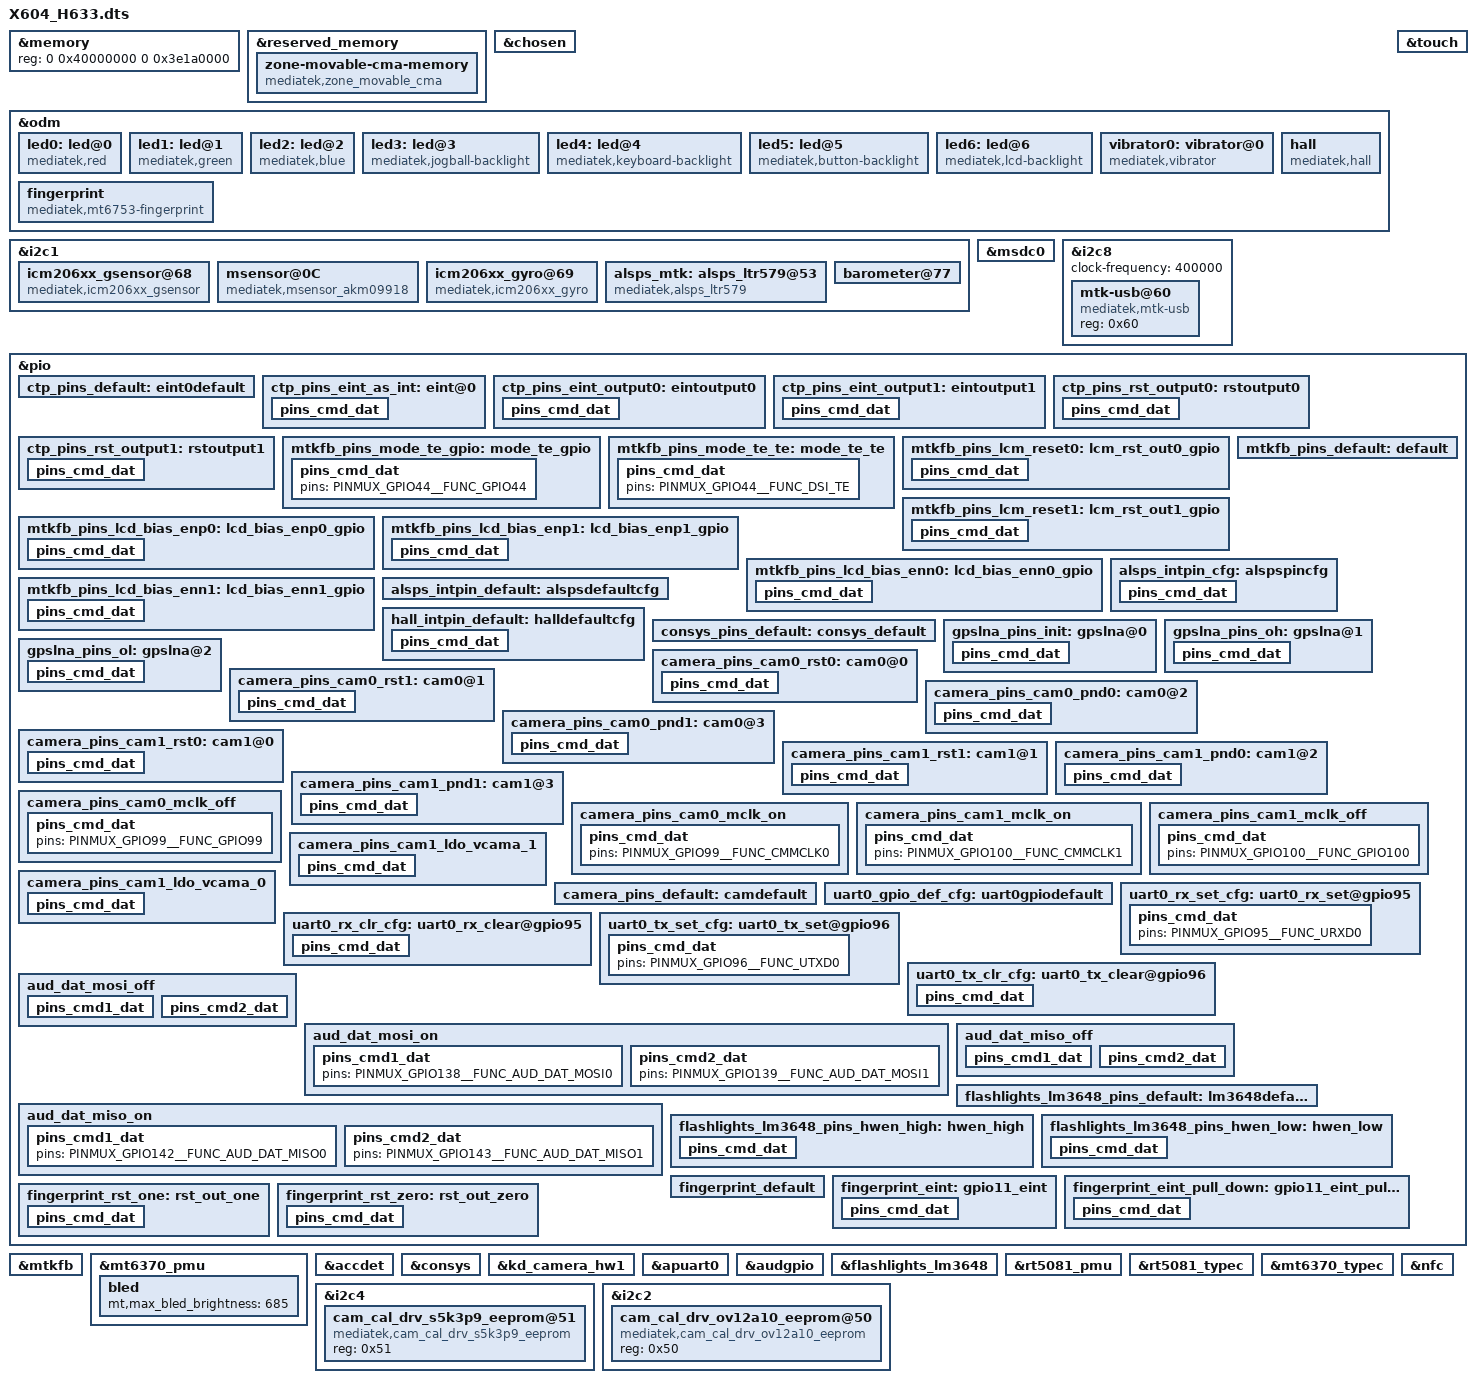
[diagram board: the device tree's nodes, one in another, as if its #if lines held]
#include <generated/autoconf.h>
/dts-v1/;

#ifdef CONFIG_MTK_DTBO_FEATURE
/plugin/;
#include <dt-bindings/interrupt-controller/irq.h>
#include <dt-bindings/interrupt-controller/arm-gic.h>
#include <dt-bindings/mmc/mt6763-msdc.h>
#include <dt-bindings/pinctrl/mt6763-pinfunc.h>
#else
#include "mt6763.dts"
#endif


&memory {
		device_type = "memory";
		reg = <0 0x40000000 0 0x3e1a0000>;
};

&reserved_memory {
		#address-cells = <2>;
		#size-cells = <2>;
		ranges;

		zone-movable-cma-memory {
			compatible = "mediatek,zone_movable_cma";
			size = <0 0xffc00000>;
			alignment = <0 0x10000000>;
			alloc-ranges = <0 0xc0000000 1 0x00000000>;
	};
};


/* chosen */
&chosen {
		bootargs = "console=tty0 console=ttyMT0,921600n1 root=/dev/ram initrd=0x45000000,\
0x1000000 loglevel=8 androidboot.selinux=permissive androidboot.hardware=mt6763 initcall_debug=1 maxcpus=1";
		/* fpga may has no lk, we need to specify display info here */
		/* fb buffer is reserved using this dts by memory node above */
		atag,videolfb-fb_base_h = <0x0>;
		atag,videolfb-fb_base_l = <0x5e605000>;
		atag,videolfb-islcmfound = <1>;
		/* because no lk, so lcm is not inited */
		atag,videolfb-islcm_inited = <0>;
		atag,videolfb-fps= <6000>;
		atag,videolfb-vramSize= <0x017bb000>;
		atag,videolfb-lcmname= "nt35695B_fhd_dsi_cmd_auo_rt5081_drv";
};

&odm {
	led0:led@0 {
		compatible = "mediatek,red";
		led_mode = <0>;
		data = <1>;
		pwm_config = <0 0 0 0 0>;
	};
	led1:led@1 {
		compatible = "mediatek,green";
		led_mode = <0>;
		data = <1>;
		pwm_config = <0 0 0 0 0>;
	};
	led2:led@2 {
		compatible = "mediatek,blue";
		led_mode = <0>;
		data = <1>;
		pwm_config = <0 0 0 0 0>;
	};
	led3:led@3 {
		compatible = "mediatek,jogball-backlight";
		led_mode = <0>;
		data = <1>;
		pwm_config = <0 0 0 0 0>;
	};
	led4:led@4 {
		compatible = "mediatek,keyboard-backlight";
		led_mode = <0>;
		data = <1>;
		pwm_config = <0 0 0 0 0>;
	};
	led5:led@5 {
		compatible = "mediatek,button-backlight";
		led_mode = <0>;
		data = <1>;
		pwm_config = <0 0 0 0 0>;
	};
	led6:led@6 {
		compatible = "mediatek,lcd-backlight";
		led_mode = <5>;
		data = <1>;
		pwm_config = <0 3 0 0 0>;
	};
	vibrator0:vibrator@0 {
		compatible = "mediatek,vibrator";
		vib_timer = <25>;
		vib_limit = <9>;
		vib_vol= <11>;
	};
        hall: hall {
                compatible = "mediatek,hall";
                interrupt-parent = <&eintc>;
                interrupts = <7 IRQ_TYPE_LEVEL_LOW>;
                debounce = <7 0>;
                pinctrl-names = "default";
                pinctrl-0 = <&hall_intpin_default>;
                status = "okay";
        };
	/*add fingerprint by sunware*/
	fingerprint:fingerprint {
		compatible = "mediatek,mt6753-fingerprint";
		interrupt-parent = <&eintc>;
		interrupts = <8 1>;
		debounce = <8 0>;

		pinctrl-names ="fingerprint_default",
			"fingerprint_pin_irq",
			"fingerprint_eint_pull_down",
			"fingerprint_reset_high",
			"fingerprint_reset_low",
			"fingerprint_power_high",
			"fingerprint_power_low";

		pinctrl-0 = <&fingerprint_default>;
		pinctrl-1 = <&fingerprint_eint>;
		pinctrl-2 = <&fingerprint_eint_pull_down>;
		pinctrl-3 = <&fingerprint_rst_one>;
		pinctrl-4 = <&fingerprint_rst_zero>;
		status = "okay";
	};
        /*add OSODEV-1176 by chengwenwu 20171123 end*/
};

&i2c1 {
/*  start sensor */
	icm206xx_gsensor@68 {
                compatible = "mediatek,icm206xx_gsensor";
		i2c_num	= <1>;
                reg = <0x68>;
                i2c_addr = <0x68 0 0 0>;
                direction = <4>;
		power_id = <0xffff>;
		power_vol = <0>;
		firlen = <0>;
		is_batch_supported = <0>;
                status = "okay";
	};

	msensor@0C {
		compatible = "mediatek,msensor_akm09918";
		i2c_num = <1>;
		reg = <0x0C>;
		i2c_addr = <0x0C 0 0 0>;
		direction = <5>;
		power_id = <0xffff>;
		power_vol = <0>;
		is_batch_supported = <0>;
		status = "okay";
	};

	icm206xx_gyro@69 {
                compatible = "mediatek,icm206xx_gyro";
                i2c_num = <1>;
                reg = <0x69>;
		i2c_addr = <0x68 0 0 0>;
		direction = <4>;
		power_id = <0xffff>;
		power_vol = <0>;
		firlen = <0>;
		is_batch_supported = <0>;
                status = "okay";
	};

        alsps_mtk:alsps_ltr579@53 {
                compatible = "mediatek,alsps_ltr579";
                pinctrl-names = "pin_default", "pin_cfg";
                pinctrl-0 = <&alsps_intpin_default>;
                pinctrl-1 = <&alsps_intpin_cfg>;
                interrupt-parent = <&eintc>;
                interrupts = <5 IRQ_TYPE_LEVEL_LOW>;
                debounce = <5 0>;
                status = "okay";
                /* customization */
                i2c_num = <1>;
                reg = <0x53>;
                i2c_addr = <0x53 0 0 0>;
                polling_mode_ps = <0>;
                polling_mode_als = <1>;
                power_id = <0xffff>;
                power_vol = <0>;
                als_level = <0 110 220 340 570 900 1130 1600 2000 4000 12000 25000 30000 40000 60000>;
                als_value = <0 100 200 300 500 800 1000 1200 1500 3000 8000 15000 20000 20000 20000 20000>;
                ps_dynamic_cali = <55 105 115 125 135 145 155 1600 20 40 50 60 70 80 90 1550>;
                ps_setting = <0x36 0x10 0x5c 100 0x01>;
                als_setting = <0x22 0x04 100 48 10 4368 4927 3790 4776>;
                ps_threshold_high =  <500>;
                ps_threshold_low =  <400>;
                is_batch_supported_ps = <0>;
                is_batch_supported_als = <0>;
        };

	barometer@77 {
		i2c_num = <1>;
		i2c_addr = <0x77 0 0 0>;
		direction = <0>;
		power_id = <0xffff>;
		power_vol = <0>;
		firlen = <32>;
		is_batch_supported = <0>;
	};
/* end sensor */
};

&msdc0 {
	status = "okay";
};

&i2c8 {
	#address-cells = <1>;
	#size-cells = <0>;
	clock-frequency = <400000>;

	mtk-usb@60 {
		compatible = "mediatek,mtk-usb";
		reg = <0x60>;
		status = "okay";
	};
};

/* TOUCH start */
&touch {
	tpd-resolution = <1080 1920>;
	use-tpd-button = <1>;
	tpd-key-num = <3>;
	tpd-key-local= <139 172 158 0>;
	tpd-key-dim-local = <90 883 100 40 230 883 100 40 370 883 100 40 0 0 0 0>;
	tpd-max-touch-num = <5>;
	tpd-filter-enable = <1>;
	tpd-filter-pixel-density = <146>;
	tpd-filter-custom-prameters = <0 0 0 0 0 0 0 0 0 0 0 0>;
	tpd-filter-custom-speed = <0 0 0>;
	pinctrl-names = "default", "state_eint_as_int", "state_eint_output0", "state_eint_output1",
		"state_rst_output0", "state_rst_output1";
	pinctrl-0 = <&ctp_pins_default>;
	pinctrl-1 = <&ctp_pins_eint_as_int>;
	pinctrl-2 = <&ctp_pins_eint_output0>;
	pinctrl-3 = <&ctp_pins_eint_output1>;
	pinctrl-4 = <&ctp_pins_rst_output0>;
	pinctrl-5 = <&ctp_pins_rst_output1>;
	status = "okay";
};
&pio {
	ctp_pins_default: eint0default {
	};
	ctp_pins_eint_as_int: eint@0 {
		pins_cmd_dat {
			pins = <PINMUX_GPIO1__FUNC_GPIO1>;
			slew-rate = <0>;
			bias-disable;
		};
	};
	ctp_pins_eint_output0: eintoutput0 {
		pins_cmd_dat {
			pins = <PINMUX_GPIO1__FUNC_GPIO1>;
			slew-rate = <1>;
			output-low;
		};
	};
	ctp_pins_eint_output1: eintoutput1 {
		pins_cmd_dat {
			pins = <PINMUX_GPIO1__FUNC_GPIO1>;
			slew-rate = <1>;
			output-high;
		};
	};
	ctp_pins_rst_output0: rstoutput0 {
		pins_cmd_dat {
			pins = <PINMUX_GPIO2__FUNC_GPIO2>;
			slew-rate = <1>;
			output-low;
		};
	};
	ctp_pins_rst_output1: rstoutput1 {
		pins_cmd_dat {
			pins = <PINMUX_GPIO2__FUNC_GPIO2>;
			slew-rate = <1>;
			output-high;
		};
	};
};
/* TOUCH end */

&pio {

	mtkfb_pins_mode_te_gpio: mode_te_gpio {
		pins_cmd_dat {
			pins = <PINMUX_GPIO44__FUNC_GPIO44>;
		};
	};

	mtkfb_pins_mode_te_te: mode_te_te {
		pins_cmd_dat {
			pins = <PINMUX_GPIO44__FUNC_DSI_TE>;
		};
	};

	mtkfb_pins_lcm_reset0: lcm_rst_out0_gpio {
		pins_cmd_dat {
			pins = <PINMUX_GPIO45__FUNC_GPIO45>;
			slew-rate = <1>;
			output-low;
		};
	};

	mtkfb_pins_lcm_reset1: lcm_rst_out1_gpio {
		pins_cmd_dat {
			pins = <PINMUX_GPIO45__FUNC_GPIO45>;
			slew-rate = <1>;
			output-high;
		};
	};

	mtkfb_pins_lcd_bias_enp0: lcd_bias_enp0_gpio {
		pins_cmd_dat {
			pins = <PINMUX_GPIO13__FUNC_GPIO13>;
			slew-rate = <1>;
			output-low;
		};
	};

	mtkfb_pins_lcd_bias_enp1: lcd_bias_enp1_gpio {
		pins_cmd_dat {
			pins = <PINMUX_GPIO13__FUNC_GPIO13>;
			slew-rate = <1>;
			output-high;
		};
	};

	mtkfb_pins_lcd_bias_enn0: lcd_bias_enn0_gpio {
		pins_cmd_dat {
			pins = <PINMUX_GPIO14__FUNC_GPIO14>;
			slew-rate = <1>;
			output-low;
		};
	};

	mtkfb_pins_lcd_bias_enn1: lcd_bias_enn1_gpio {
		pins_cmd_dat {
			pins = <PINMUX_GPIO14__FUNC_GPIO14>;
			slew-rate = <1>;
			output-high;
		};
	};
	mtkfb_pins_default: default {
	};

};

&mtkfb {
	pinctrl-names = "default", "mode_te_gpio", "mode_te_te", "lcm_rst_out0_gpio",
	"lcm_rst_out1_gpio", "lcd_bias_enp0_gpio", "lcd_bias_enp1_gpio";
	pinctrl-0 = <&mtkfb_pins_default>;
	pinctrl-1 = <&mtkfb_pins_mode_te_gpio>;
	pinctrl-2 = <&mtkfb_pins_mode_te_te>;
	pinctrl-3 = <&mtkfb_pins_lcm_reset0>;
	pinctrl-4 = <&mtkfb_pins_lcm_reset1>;
	pinctrl-5 = <&mtkfb_pins_lcd_bias_enp0>;
	pinctrl-6 = <&mtkfb_pins_lcd_bias_enp1>;
	pinctrl-7 = <&mtkfb_pins_lcd_bias_enn0>;
	pinctrl-8 = <&mtkfb_pins_lcd_bias_enn1>;
	status = "okay";
};

&mt6370_pmu {
	bled {
		mt,max_bled_brightness = <685>; /* we have 11 bit resolution, quantize in driver */
						/* maximum 2047 */
	};
};

/* sensor gpio standization */
&pio {
	alsps_intpin_cfg: alspspincfg {

		pins_cmd_dat {
			pins = <PINMUX_GPIO5__FUNC_GPIO5>;
			slew-rate = <0>;
			bias-pull-up = <00>;
		};
	};

	alsps_intpin_default: alspsdefaultcfg {

	};
        hall_intpin_default: halldefaultcfg {
                pins_cmd_dat {
                        pins = <PINMUX_GPIO7__FUNC_GPIO7>;
                        slew-rate = <0>;
                        bias-pull-up = <00>;
                        status = "okay";
                };
        };
};
/* sensor end */

/* accdet start */
&accdet {
	/* accdet micbias voltage: 0x07,2.7v;0x05,2.5v;0x02,1.9v */
	accdet-mic-vol = <6>;
	headset-mode-setting = <0x500 0x500 1 0x1f0 0x800 0x800 0x20 0x44>;
	accdet-plugout-debounce = <1>;
	/*1:ACC mode, 2:low cost without in bias, 6:low cost with in bias*/
	accdet-mic-mode = <2>;
	/* eint_level_trigger: 8,LEVEL_LOW(default);4,LEVEL_HIGH;others,LEVEL_LOW */
	headset-eint-level-pol = <8>;
	/*0--MD_MAX--UP_MAX--DW_MAX*/
	headset-three-key-threshold = <0 80 220 400>;
	headset-three-key-threshold-CDD = <0 121 192 600>;
	/*0--MD_MAX--VOICE_MAX--UP_MAX--DW_MAX*/
	headset-four-key-threshold = <0 58 121 192 400>;
	status = "okay";
};
/* accdet end */

/* CONSYS GPIO standardization */
&pio {
	consys_pins_default: consys_default {
	};
	gpslna_pins_init: gpslna@0 {
		pins_cmd_dat {
			pins = <PINMUX_GPIO107__FUNC_GPIO107>;
			slew-rate = <0>;
			bias-disable;
			output-low;
		};
	};
	gpslna_pins_oh: gpslna@1 {
		pins_cmd_dat {
			pins = <PINMUX_GPIO107__FUNC_GPIO107>;
			slew-rate = <1>;
			output-high;
		};
	};
	gpslna_pins_ol: gpslna@2 {
		pins_cmd_dat {
			pins = <PINMUX_GPIO107__FUNC_GPIO107>;
			slew-rate = <1>;
			output-low;
		};
	};
};
&consys {
	pinctrl-names = "default", "gps_lna_state_init", "gps_lna_state_oh", "gps_lna_state_ol";
	pinctrl-0 = <&consys_pins_default>;
	pinctrl-1 = <&gpslna_pins_init>;
	pinctrl-2 = <&gpslna_pins_oh>;
	pinctrl-3 = <&gpslna_pins_ol>;
	status = "okay";
};
/* CONSYS end */

 /* CAMERA GPIO standardization */
&pio {
	camera_pins_cam0_rst0: cam0@0 {
		pins_cmd_dat {
			pins = <PINMUX_GPIO101__FUNC_GPIO101>;
			slew-rate = <1>; /*direction 0:in, 1:out*/
			output-low;/*direction out used only. output_low or high*/
		};
	};
	camera_pins_cam0_rst1: cam0@1 {
		pins_cmd_dat {
			pins = <PINMUX_GPIO101__FUNC_GPIO101>;
			slew-rate = <1>;
			output-high;
		};
	};
	camera_pins_cam0_pnd0: cam0@2 {
		pins_cmd_dat {
			pins = <PINMUX_GPIO97__FUNC_GPIO97>;
			slew-rate = <1>;
			output-low;
		};
	};
	camera_pins_cam0_pnd1: cam0@3 {
		pins_cmd_dat {
			pins = <PINMUX_GPIO97__FUNC_GPIO97>;
			slew-rate = <1>;
			output-high;
		};
	};
	camera_pins_cam1_rst0: cam1@0 {
		pins_cmd_dat {
			pins = <PINMUX_GPIO102__FUNC_GPIO102>;
			slew-rate = <1>; /*direction 0:in, 1:out*/
			output-low;/*direction out used only. output_low or high*/
		};
	};
	camera_pins_cam1_rst1: cam1@1 {
		pins_cmd_dat {
			pins = <PINMUX_GPIO102__FUNC_GPIO102>;
			slew-rate = <1>;
			output-high;
		};
	};
	camera_pins_cam1_pnd0: cam1@2 {
		pins_cmd_dat {
			pins = <PINMUX_GPIO98__FUNC_GPIO98>;
			slew-rate = <1>;
			output-low;
		};
	};
	camera_pins_cam1_pnd1: cam1@3 {
		pins_cmd_dat {
			pins = <PINMUX_GPIO98__FUNC_GPIO98>;
			slew-rate = <1>;
			output-high;
		};
	};
	camera_pins_cam0_mclk_on: camera_pins_cam0_mclk_on {
		pins_cmd_dat {
			pins = <PINMUX_GPIO99__FUNC_CMMCLK0>;
		};
	};
	camera_pins_cam0_mclk_off: camera_pins_cam0_mclk_off {
		pins_cmd_dat {
			pins = <PINMUX_GPIO99__FUNC_GPIO99>;
		};
	};
	camera_pins_cam1_mclk_on: camera_pins_cam1_mclk_on {
		pins_cmd_dat {
			pins = <PINMUX_GPIO100__FUNC_CMMCLK1>;
		};
	};
	camera_pins_cam1_mclk_off: camera_pins_cam1_mclk_off {
		pins_cmd_dat {
			pins = <PINMUX_GPIO100__FUNC_GPIO100>;
		};
	};
	camera_pins_cam1_ldo_vcama_1: camera_pins_cam1_ldo_vcama_1 {
		pins_cmd_dat {
			pins = <PINMUX_GPIO20__FUNC_GPIO20>;
			slew-rate = <1>;
			output-high;
			//pins = <PINMUX_GPIO52__FUNC_BPI_ANT2>;
		};
	};
	camera_pins_cam1_ldo_vcama_0: camera_pins_cam1_ldo_vcama_0 {
		pins_cmd_dat {
			pins = <PINMUX_GPIO20__FUNC_GPIO20>;
			slew-rate = <1>;
			output-low;
			//pins = <PINMUX_GPIO52__FUNC_GPIO52>;
		};
	};
	camera_pins_default: camdefault {
	};

};

&kd_camera_hw1 {
	pinctrl-names = "default",
			"cam0_rst0", "cam0_rst1", "cam0_pnd0", "cam0_pnd1",
			"cam1_rst0", "cam1_rst1", "cam1_pnd0", "cam1_pnd1",
			"cam0_mclk_on", "cam0_mclk_off",
			"cam1_mclk_on", "cam1_mclk_off",
			"cam1_ldo_vcama_1","cam1_ldo_vcama_0";

	pinctrl-0 = <&camera_pins_default>;
	pinctrl-1 = <&camera_pins_cam0_rst0>;
	pinctrl-2 = <&camera_pins_cam0_rst1>;
	pinctrl-3 = <&camera_pins_cam0_pnd0>;
	pinctrl-4 = <&camera_pins_cam0_pnd1>;
	pinctrl-5 = <&camera_pins_cam1_rst0>;
	pinctrl-6 = <&camera_pins_cam1_rst1>;
	pinctrl-7 = <&camera_pins_cam1_pnd0>;
	pinctrl-8 = <&camera_pins_cam1_pnd1>;
	pinctrl-9 = <&camera_pins_cam0_mclk_on>;
	pinctrl-10 = <&camera_pins_cam0_mclk_off>;
	pinctrl-11 = <&camera_pins_cam1_mclk_on>;
	pinctrl-12 = <&camera_pins_cam1_mclk_off>;
	pinctrl-13 = <&camera_pins_cam1_ldo_vcama_1>;
	pinctrl-14 = <&camera_pins_cam1_ldo_vcama_0>;
	status = "okay";

};
/* CAMERA GPIO end */

/* UART GPIO */
&apuart0 {
	pinctrl-names = "uart0_gpio_default",
			"uart0_rx_set",
			"uart0_rx_clear",
			"uart0_tx_set",
			"uart0_tx_clear";
	pinctrl-0 = <&uart0_gpio_def_cfg>;
	pinctrl-1 = <&uart0_rx_set_cfg>;
	pinctrl-2 = <&uart0_rx_clr_cfg>;
	pinctrl-3 = <&uart0_tx_set_cfg>;
	pinctrl-4 = <&uart0_tx_clr_cfg>;
	status = "okay";
};

&pio {
	/* UART GPIO Settings - Start */
	/* UART0: rx set, rx clear, tx clear, tx clear*/
	uart0_gpio_def_cfg:uart0gpiodefault {

	};
	uart0_rx_set_cfg:uart0_rx_set@gpio95 {
		pins_cmd_dat {
			pins = <PINMUX_GPIO95__FUNC_URXD0>;
		};
	};
	uart0_rx_clr_cfg:uart0_rx_clear@gpio95 {
		pins_cmd_dat {
			pins = <PINMUX_GPIO95__FUNC_GPIO95>;
			slew-rate = <1>;
			output-high;
		};
	};
	uart0_tx_set_cfg:uart0_tx_set@gpio96 {
		pins_cmd_dat {
			pins = <PINMUX_GPIO96__FUNC_UTXD0>;
		};
	};
	uart0_tx_clr_cfg:uart0_tx_clear@gpio96 {
		pins_cmd_dat {
			pins = <PINMUX_GPIO96__FUNC_GPIO96>;
			slew-rate = <1>;
			output-high;
		};
	};
};/* UART GPIO end */

/* IRTX GPIO end */
/*
&irtx_pwm {
	pinctrl-names = "irtx_gpio_led_default", "irtx_gpio_led_set";
	pinctrl-0 = <&irtx_gpio_led_default>;
	pinctrl-1 = <&irtx_gpio_led_set>;
	status = "disabled";
};
&pio {
	// * IRTX GPIO Settings -Start * /
	// * default: GPIO0, output, high * /
	irtx_gpio_led_default:irtx_gpio_led_def@gpio58 {
		pins_cmd_dat {
			pins = <PINMUX_GPIO58__FUNC_GPIO58>;
			slew-rate = <1>;
			bias-disable;
			output-low;
			input-schmitt-enable = <0>;
		};
	};

	irtx_gpio_led_set:irtx_gpio_led_set@gpio58 {
		pins_cmd_dat {
			pins = <PINMUX_GPIO58__FUNC_PWM_B>;
			slew-rate = <1>;
			output-high;
		};
	};
}; */ /* IRTX GPIO Settings -End */

/* AUDIO GPIO standardization */
&audgpio {
        extamp_gpio = <&pio 92 0>;
        extamp_mode = <3>;
        extamp_speech_mode = <3>;
	pinctrl-names = "aud_dat_mosi_off",
			"aud_dat_mosi_on",
			"aud_dat_miso_off",
			"aud_dat_miso_on";
	pinctrl-0 = <&aud_dat_mosi_off>;
	pinctrl-1 = <&aud_dat_mosi_on>;
	pinctrl-2 = <&aud_dat_miso_off>;
	pinctrl-3 = <&aud_dat_miso_on>;
	status = "okay";
};

&pio {
	aud_dat_mosi_off: aud_dat_mosi_off {
		pins_cmd1_dat {
			pins = <PINMUX_GPIO138__FUNC_GPIO138>;
			input-enable;
			slew-rate = <0>;
			bias-disable;
		};
		pins_cmd2_dat {
			pins = <PINMUX_GPIO139__FUNC_GPIO139>;
			input-enable;
			slew-rate = <0>;
			bias-disable;
		};
	};

	aud_dat_mosi_on: aud_dat_mosi_on {
		pins_cmd1_dat {
			pins = <PINMUX_GPIO138__FUNC_AUD_DAT_MOSI0>;
		};
		pins_cmd2_dat {
			pins = <PINMUX_GPIO139__FUNC_AUD_DAT_MOSI1>;
		};
	};

	aud_dat_miso_off: aud_dat_miso_off {
		pins_cmd1_dat {
			pins = <PINMUX_GPIO142__FUNC_GPIO142>;
			input-enable;
			slew-rate = <0>;
			bias-disable;
		};
		pins_cmd2_dat {
			pins = <PINMUX_GPIO143__FUNC_GPIO143>;
			input-enable;
			slew-rate = <0>;
			bias-disable;
		};
	};

	aud_dat_miso_on: aud_dat_miso_on {
		pins_cmd1_dat {
			pins = <PINMUX_GPIO142__FUNC_AUD_DAT_MISO0>;
		};
		pins_cmd2_dat {
			pins = <PINMUX_GPIO143__FUNC_AUD_DAT_MISO1>;
		};
	};
};
/* AUDIO end */
&pio {
	flashlights_lm3648_pins_default: lm3648default {
	};

	flashlights_lm3648_pins_hwen_high: hwen_high {
		pins_cmd_dat {
			pins = <PINMUX_GPIO90__FUNC_GPIO90>;
			slew-rate = <1>;
			output-high;
		};
	};

	flashlights_lm3648_pins_hwen_low: hwen_low {
		pins_cmd_dat {
			pins = <PINMUX_GPIO90__FUNC_GPIO90>;
			slew-rate = <1>;
			output-low;
		};
	};
};

&flashlights_lm3648 {
	pinctrl-names = "default", "hwen_high", "hwen_low";
	pinctrl-0 = <&flashlights_lm3648_pins_default>;
	pinctrl-1 = <&flashlights_lm3648_pins_hwen_high>;
	pinctrl-2 = <&flashlights_lm3648_pins_hwen_low>;
	status = "okay";
};

#ifdef CONFIG_MFD_RT5081_PMU
&rt5081_pmu {
	rt,intr_gpio_num = <91>; /* direct defined GPIO num */
	rt,intr_gpio = <&pio 91 0x0>;
};
#endif
#ifdef CONFIG_TCPC_RT5081
&rt5081_typec {
	rt5081pd,intr_gpio_num = <41>; /* direct defined GPIO num */
	rt5081pd,intr_gpio = <&pio 41 0x0>;
};
#endif
#ifdef CONFIG_MFD_MT6370_PMU
&mt6370_pmu {
	mt6370,intr_gpio_num = <10>; /* direct defined GPIO num */
	mt6370,intr_gpio = <&pio 10 0x0>;
};
#endif
#ifdef CONFIG_TCPC_MT6370
&mt6370_typec {
	mt6370pd,intr_gpio_num = <11>; /* direct defined GPIO num */
	mt6370pd,intr_gpio = <&pio 11 0x0>;
};
#endif


&nfc {
	gpio-rst = <21>;
	gpio-rst-std = <&pio 21 0x0>;
	gpio-irq = <22>;
	gpio-irq-std = <&pio 22  0x0>;
};

&mtkfb {
	partial-update = <1>;
	status = "okay";
};
/*add fingerprint by sunware*/
&pio {
	fingerprint_default: fingerprint_default {
	};

	fingerprint_eint: gpio11_eint {
		pins_cmd_dat {
			pins = <PINMUX_GPIO8__FUNC_GPIO8>;
			slew-rate = <0>;
			bias-disable;
		};
	};

	fingerprint_eint_pull_down: gpio11_eint_pull_down {
		pins_cmd_dat {
			pins = <PINMUX_GPIO8__FUNC_GPIO8>;
			slew-rate = <0>;
			bias-pull-down = <00>;
			output-low;
		};
	};

	fingerprint_rst_one: rst_out_one {
		pins_cmd_dat {
			pins = <PINMUX_GPIO19__FUNC_GPIO19>;
			slew-rate = <1>;
			bias-disable;
			output-high;
		};
	};

	fingerprint_rst_zero: rst_out_zero {
		pins_cmd_dat {
			pins = <PINMUX_GPIO19__FUNC_GPIO19>;
			slew-rate = <1>;
			bias-disable;
			output-low;
		};
	};

};
/* end of fingerprint*/
&i2c4{
	cam_cal_drv_s5k3p9_eeprom@51 {
		compatible = "mediatek,cam_cal_drv_s5k3p9_eeprom";
		reg = <0x51>;
	};
};
&i2c2{
	cam_cal_drv_ov12a10_eeprom@50 {
		compatible = "mediatek,cam_cal_drv_ov12a10_eeprom";
		reg = <0x50>;
	};
};
#include <X604_H633/cust.dtsi>
/*End of this file, DO NOT ADD ANYTHING HERE*/
